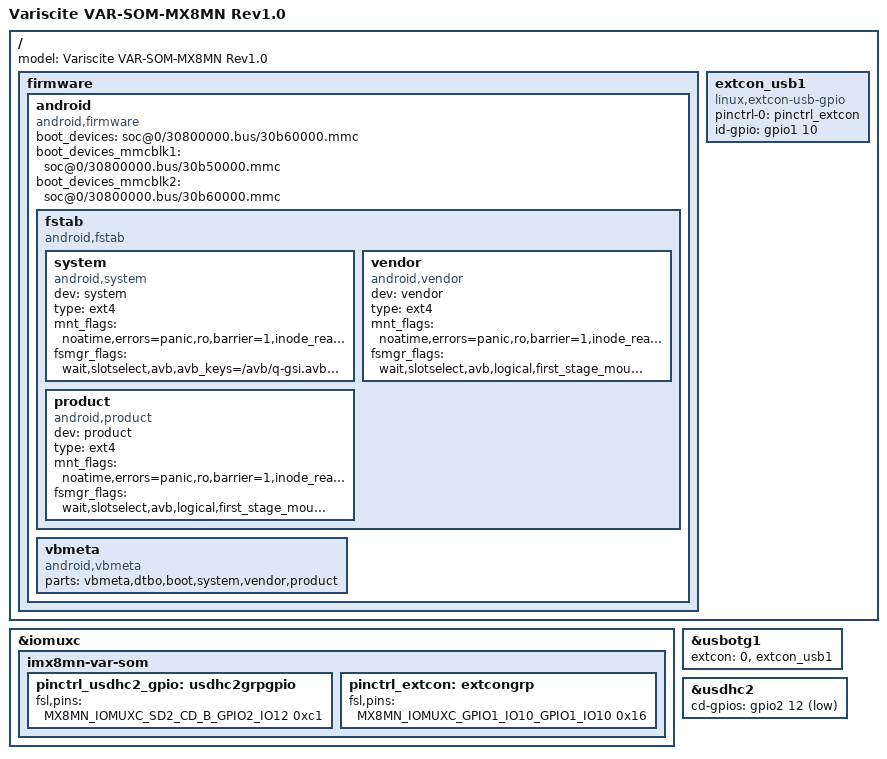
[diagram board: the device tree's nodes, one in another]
// SPDX-License-Identifier: (GPL-2.0+ OR MIT)
/*
 * Copyright 2019 NXP
 * Copyright 2019-2020 Variscite Ltd.
 */

/dts-v1/;

#include "imx8mn-var-som.dts"

/ {
	firmware {
        android {
            compatible = "android,firmware";
            boot_devices = "soc@0/30800000.bus/30b60000.mmc";
            boot_devices_mmcblk1 = "soc@0/30800000.bus/30b50000.mmc";
            boot_devices_mmcblk2 = "soc@0/30800000.bus/30b60000.mmc";
            fstab {
                compatible = "android,fstab";
                system {
                    compatible = "android,system";
                    dev = "system";
                    type = "ext4";
                    mnt_flags = "noatime,errors=panic,ro,barrier=1,inode_readahead_blks=8";
                    fsmgr_flags = "wait,slotselect,avb,avb_keys=/avb/q-gsi.avbpubkey:/avb/r-gsi.avbpubkey:/avb/s-gsi.avbpubkey,logical,first_stage_mount";
                };
                vendor {
                    compatible = "android,vendor";
                    dev = "vendor";
                    type = "ext4";
                    mnt_flags = "noatime,errors=panic,ro,barrier=1,inode_readahead_blks=8";
                    fsmgr_flags = "wait,slotselect,avb,logical,first_stage_mount";
                };
                product {
                    compatible = "android,product";
                    dev = "product";
                    type = "ext4";
                    mnt_flags = "noatime,errors=panic,ro,barrier=1,inode_readahead_blks=8";
                    fsmgr_flags = "wait,slotselect,avb,logical,first_stage_mount";
                };
            };
            vbmeta {
                compatible = "android,vbmeta";
                parts = "vbmeta,dtbo,boot,system,vendor,product";
            };
        };
    };
};


/ {
	model = "Variscite VAR-SOM-MX8MN Rev1.0";

	/* OTG ID */
	extcon_usb1: extcon_usb1 {
		compatible = "linux,extcon-usb-gpio";
		pinctrl-names = "default";
		pinctrl-0 = <&pinctrl_extcon>;
		id-gpio = <&gpio1 10 GPIO_ACTIVE_HIGH>;
		status = "okay";
	};
};

&iomuxc {
	imx8mn-var-som {
		pinctrl_usdhc2_gpio: usdhc2grpgpio {
			fsl,pins = <
				MX8MN_IOMUXC_SD2_CD_B_GPIO2_IO12	0xc1
			>;
		};

		pinctrl_extcon: extcongrp {
			fsl,pins = <
				MX8MN_IOMUXC_GPIO1_IO10_GPIO1_IO10	0x16
			>;
		};
	};
};

&usbotg1 {
	extcon = <0>, <&extcon_usb1>;
};

&usdhc2 {
	cd-gpios = <&gpio2 12 GPIO_ACTIVE_LOW>;
};
